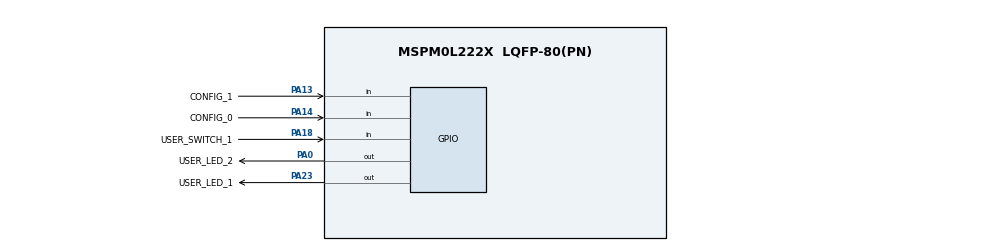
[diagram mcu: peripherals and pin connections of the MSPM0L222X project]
 // @cliArgs --device "MSPM0L222X" --package "LQFP-80(PN)" --part "Default"
// @cliArgs --board /ti/boards/LP_MSPM0L2228 --rtos nortos

/**
 * Import the modules used in this configuration.
 */
const GPIO   = scripting.addModule("/ti/driverlib/GPIO", {}, false);
const GPIO1  = GPIO.addInstance();
const GPIO2  = GPIO.addInstance();
const GPIO3  = GPIO.addInstance();
const SYSCTL = scripting.addModule("/ti/driverlib/SYSCTL");

/**
 * Write custom configuration values to the imported modules.
 */
GPIO1.$name                         = "GPIO_LEDS";
GPIO1.port                          = "PORTA";
GPIO1.associatedPins.create(2);
GPIO1.associatedPins[0].$name       = "USER_LED_1";
GPIO1.associatedPins[0].pin.$assign = "PA23";
GPIO1.associatedPins[1].$name       = "USER_LED_2";
GPIO1.associatedPins[1].pin.$assign = "PA0";

const Board = scripting.addModule("/ti/driverlib/Board", {}, false);
Board.configureUnused = true;

GPIO2.$name                         = "GPIO_SWITCH";
GPIO2.associatedPins[0].polarity    = "RISE";
GPIO2.port                          = "PORTA";
GPIO2.associatedPins[0].assignedPin = "18";
GPIO2.associatedPins[0].direction   = "INPUT";
GPIO2.associatedPins[0].$name       = "USER_SWITCH_1";
GPIO2.associatedPins[0].wakeupLogic = "ON_1";
GPIO2.associatedPins[0].pin.$assign = "PA18";

GPIO3.$name                         = "GPIO_INPUT";
GPIO3.port                          = "PORTA";
GPIO3.associatedPins.create(2);
GPIO3.associatedPins[0].$name       = "CONFIG_0";
GPIO3.associatedPins[0].direction   = "INPUT";
GPIO3.associatedPins[0].assignedPin = "14";
GPIO3.associatedPins[0].pin.$assign = "PA14";
GPIO3.associatedPins[0].internalResistor = "PULL_UP";
GPIO3.associatedPins[1].$name       = "CONFIG_1";
GPIO3.associatedPins[1].direction   = "INPUT";
GPIO3.associatedPins[1].pin.$assign = "PA13";
GPIO3.associatedPins[1].internalResistor = "PULL_UP";

SYSCTL.clockTreeEn = true;
